# psc3_p8_ppca register map
Vendor: Infineon Technologies; Series: PSC3_P8; File version: 1.0
CPU: CM33 r0p1, little endian, MPU, FPU, DSP, VTOR, 3 interrupt priority bits, 143 interrupts
Registers are 32-bit, read-write, reset 0x0 unless marked. A register's access mark holds for its fields unless they carry their own. Offsets are from the block's base; [hi:lo] are bit positions; lines under a group give offsets from that group; {n}, {i} and the like mark numbered series; 'fields as' and 'values as' point back to an identical list; <NAME> marks a mode.

## SRSS (part 2 of 2) — SRSS Core Registers
Base 0x68200000
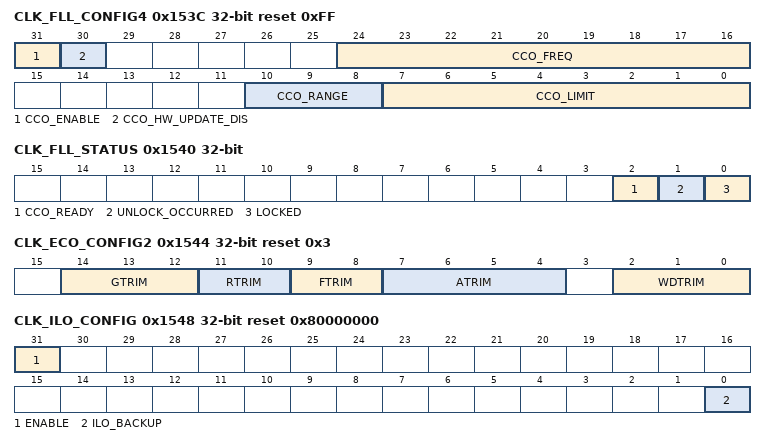
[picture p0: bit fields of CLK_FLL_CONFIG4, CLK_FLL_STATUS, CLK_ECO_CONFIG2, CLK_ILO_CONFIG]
0x153C CLK_FLL_CONFIG4 reset 0xFF — FLL Configuration Register 4
  [31] CCO_ENABLE — Enable the CCO. It is required to enable the CCO before using the FLL. 0: Block is powered off 1: Block is powered on
  [30] CCO_HW_UPDATE_DIS — Disable CCO frequency update by FLL hardware 0: Hardware update of CCO settings is allowed. Use this setting for normal FLL operation. 1: Hardware update of CCO settings is disabled. Use this setting for open-loop FLL operation.
  [24:16] CCO_FREQ — CCO frequency code. This is updated by HW when the FLL is enabled. It can be manually updated to use the CCO in an open loop configuration. The meaning of each frequency code depends on the range.
  [10:8] CCO_RANGE — Frequency range of CCO
    0=RANGE0 (Target frequency is in range [48, 64) MHz); 1=RANGE1 (Target frequency is in range [64, 85) MHz); 2=RANGE2 (Target frequency is in range [85, 113) MHz); 3=RANGE3 (Target frequency is in range [113, 150) MHz); 4=RANGE4 (Target frequency is in range [150, 200] MHz)
  [7:0] CCO_LIMIT — Maximum CCO offset allowed (used to prevent FLL dynamics from selecting an CCO frequency that the logic cannot support)
0x1540 CLK_FLL_STATUS — FLL Status Register
  [2] CCO_READY ro — This indicates that the CCO is internally settled and ready to use.
  [1] UNLOCK_OCCURRED write-1-clears — This bit sets whenever the FLL is enabled and goes out of lock. This bit stays set until cleared by firmware. Note: When exiting Deep Sleep with FLL enabled, UNLOCK_OCCURRED will set. Therefore, after FLL successfully locks, FW should clear UNLOCK_OCCURRED flag to prevent a false positive that would indicate that FLL erroneously unlocked.
  [0] LOCKED ro — FLL Lock Indicator
0x1544 CLK_ECO_CONFIG2 reset 0x3 — ECO Configuration Register 2
  [14:12] GTRIM — Gain Trim - Startup time.
  [11:10] RTRIM — Feedback resistor Trim
  [9:8] FTRIM — Filter Trim - 3rd harmonic oscillation
  [7:4] ATRIM — Amplitude trim to set the crystal drive level when ECO_CONFIG.AGC_EN=1. WARNING: use care when setting this field because driving a crystal beyond its rated limit can permanently damage the crystal. 0x0 - 150mV 0x1 - 175mV 0x2 - 200mV 0x3 - 225mV 0x4 - 250mV 0x5 - 275mV 0x6 - 300mV 0x7 - 325mV 0x8 - 350mV 0x9 - 375mV 0xA - 400mV 0xB - 425mV 0xC - 450mV 0xD - 475mV 0xE - 500mV 0xF - 525mV
  [2:0] WDTRIM — Watch Dog Trim - Delta voltage below steady state level 0x0 - 50mV 0x1 - 75mV 0x2 - 100mV 0x3 - 125mV 0x4 - 150mV 0x5 - 175mV 0x6 - 200mV 0x7 - 225mV
0x1548 CLK_ILO_CONFIG reset 0x80000000 — ILO Configuration
  [31] ENABLE — Master enable for ILO. Writes to this field are ignored unless the WDT is unlocked using WDT_LOCK register. After enabling, it takes at most two cycles to reach the accuracy spec.
  [0] ILO_BACKUP — When BACKUP_PRESENT=0, ILO_BACKUP will not be generated so enabling/disabling ILO will only be controlled by the enable bit. If backup domain is present on this product, this register indicates that ILO should stay enabled for use by backup domain during XRES, HIBERNATE mode, and through power-related resets like BOD on VDDD/VCCD. Writes to this field are ignored unless the WDT is unlocked using WDT_LOCK register. 0: ILO turns off at XRES/BOD event or HIBERNATE entry. 1: ILO remains on if backup domain is present and powered even for XRES/BOD or HIBERNATE entry.
0x154C CLK_TRIM_ILO_CTL reset 0x2C — ILO Trim Register
  [5:0] ILO_FTRIM — IL0 frequency trims. LSB step size is 1.5 percent (typical) of the frequency.
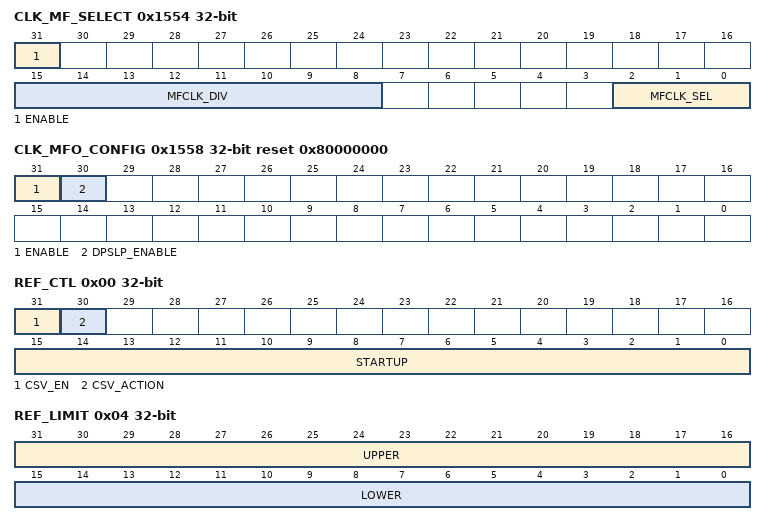
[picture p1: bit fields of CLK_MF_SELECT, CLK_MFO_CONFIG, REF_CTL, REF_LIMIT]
0x1554 CLK_MF_SELECT — Medium Frequency Clock Select Register
  [31] ENABLE — Enable for MFCLK (clk_mf). When disabling clk_mf, do not disable the source until after 5 clk_mf periods. clk_mf continues to operate in DEEPSLEEP for compatible sources. Firmware must disable clk_mf before entering DEEPSLEEP if the source is not compatible with DEEPSLEEP mode.
  [15:8] MFCLK_DIV — Divide selected clock source by (1+MFCLK_DIV). The output of this divider is MFCLK (clk_mf). Allows for integer divisions in the range [1, 256]. Do not change this setting while ENABLE==1.
  [2:0] MFCLK_SEL — Select source for MFCLK (clk_mf). Note that not all products support all clock sources. Selecting a clock source that is not supported results in undefined behavior.
    0=MFO (MFO - Medium Frequency Oscillator. DEEPSLEEP compatibility is product-specific. See CLK_MFO_CONFIG for capability of this product.); 1=ILO (ILO - Internal Low-speed Oscillator.); 2=WCO (WCO - Watch-Crystal Oscillator, if present.); 3=ALTLF (ALTLF - Alternate Low-Frequency Clock. Capability is product-specific); 4=PILO (PILO - Precision ILO, if present.); 5=ILO1 (ILO1 - Internal Low-speed Oscillator #1, if present.); 6=ECO_PRESCALER (ECO_PRESCALER - External-Crystal Oscillator, if present, after prescaling in CLK_ECO_PRESCALE. Intended for applications that operate in ACTIVE/SLEEP modes only. Does not work in DEEPSLEEP mode.); 7=LPECO (LPECO - Low Power External Crystal Oscillator, if present.)
0x1558 CLK_MFO_CONFIG reset 0x80000000 — MFO Configuration Register
  [31] ENABLE — Enable for Medium Frequency Oscillator (MFO) to generate clk_mf. It is product-specific whether this is a separate component or implemented as a divided version of another clock (eg. IMO).
  [30] DPSLP_ENABLE — Enable for MFO during DEEPSLEEP. This bit is ignored when ENABLE==0. When ENABLE==1: 0: MFO is automatically disabled during DEEPSLEEP and enables upon wakeup; 1: MFO is kept enabled throughout DEEPSLEEP
0x1560 CLK_IHO_CONFIG reset 0x80000000 — IHO Configuration Register
  [31] ENABLE — Enable for Internal High-speed Oscillator (IHO) to generate clk_iho.
0x1700 CSV_REF_SEL — Select CSV Reference clock for Active domain
  [2:0] REF_MUX — Selects a source for clock clk_ref_hf. Note that not all products support all clock sources. Selecting a clock source that is not supported will result in undefined behavior. It takes four cycles of the originally selected clock to switch away from it. Do not disable the original clock during this time.
    0=IMO (IMO - Internal R/C Oscillator); 1=EXTCLK (EXTCLK - External Clock Pin); 2=ECO (ECO - External-Crystal Oscillator); 3=ALTHF (ALTHF - Alternate High-Frequency clock input (product-specific clock)); 4=IHO (IHO - Internal High-speed Oscillator)
0x1710 CSV_REF group — CSV registers for the CSV Reference clock
  0x00 CSV group — Active domain Clock Supervisor (CSV) registers for CSV Reference clock
    0x00 REF_CTL — Clock Supervision Reference Control
      [31] CSV_EN — Enables clock supervision, both frequency and loss. CSV in Active domain: Clock supervision is reset during DeepSleep and Hibernate modes. When enabled it begins operating automatically after a DeepSleep wakeup, but it must be reconfigured after Hibernate wakeup. CSV in DeepSleep domain: Clock supervision is reset during Hibernate mode. It must be reconfigured after Hibernate wakeup. A CSV error detection is reported to the Fault structure, or instead it can generate a power reset.
      [30] CSV_ACTION — Specifies the action taken when an anomaly is detected on the monitored clock. CSV in DeepSleep domain always do a Fault report (which also wakes up the system).
        0=FAULT (Generate a fault); 1=RESET (Cause a power reset. This should only be used for clk_hf0.)
      [15:0] STARTUP — Startup delay time -1 (in reference clock cycles), after enable or DeepSleep wakeup, from reference clock start to monitored clock start. At a minimum (both clocks running): STARTUP >= (PERIOD +3) * FREQ_RATIO - UPPER, with FREQ_RATIO = (Reference frequency / Monitored frequency) On top of that the actual clock startup delay and the margin for accuracy of both clocks must be added.
    0x04 REF_LIMIT — Clock Supervision Reference Limits
      [31:16] UPPER — Cycle time upper limit. Set the upper limit -1, in reference clock cycles, before (or same time) the next monitored clock event must happen. If a monitored clock event does not happen before this limit is reached, or does not happen at all (clock loss), a CSV error is detected.
      [15:0] LOWER — Cycle time lower limit. Set the lower limit -1, in reference clock cycles, before the next monitored clock event is allowed to happen. If a monitored clock event happens before this limit is reached a CSV error is detected. LOWER must be at least 1 less than UPPER. In case the clocks are asynchronous LOWER must be at least 3 less than UPPER.
    0x08 MON_CTL — Clock Supervision Monitor Control
      [15:0] PERIOD — Period time. Set the Period -1, in monitored clock cycles, before the next monitored clock event happens. PERIOD <= (UPPER+1) / FREQ_RATIO -1, with FREQ_RATIO = (Reference frequency / Monitored frequency) In case the clocks are asynchronous: PERIOD <= UPPER / FREQ_RATIO -1 Additionally margin must be added for accuracy of both clocks.
0x1720 CSV_LF group — CSV registers for LF clock
  0x00 CSV group — LF clock Clock Supervisor registers
    0x00 REF_CTL — Clock Supervision Reference Control
      [31] CSV_EN — Enables clock supervision, both frequency and loss. CSV in Active domain: Clock supervision is reset during DeepSleep and Hibernate modes. When enabled it begins operating automatically after a DeepSleep wakeup, but it must be reconfigured after Hibernate wakeup. CSV in DeepSleep domain: Clock supervision is reset during Hibernate mode. It must be reconfigured after Hibernate wakeup. CSV in Backup domain: Clock supervision operates during Hibernate mode, can be configured to wake from Hibernate, and continues operating during reboot. A CSV error detection is reported to the Fault structure.
      [7:0] STARTUP — Startup delay time -1 (in reference clock cycles), after enable, from reference clock start to monitored clock start. At a minimum (both clocks running): STARTUP >= (PERIOD +3) * FREQ_RATIO - UPPER, with FREQ_RATIO = (Reference frequency / Monitored frequency) On top of that the actual clock startup delay and the margin for accuracy of both clocks must be added.
    0x04 REF_LIMIT — Clock Supervision Reference Limits
      [23:16] UPPER — Cycle time upper limit. Set the upper limit -1, in reference clock cycles, before (or same time) the next monitored clock event must happen. If a monitored clock event does not happen before this limit is reached, or does not happen at all (clock loss), a CSV error is detected.
      [7:0] LOWER — Cycle time lower limit. Set the lower limit -1, in reference clock cycles, before the next monitored clock event is allowed to happen. If a monitored clock event happens before this limit is reached a CSV error is detected. LOWER must be at least 1 less than UPPER. In case the clocks are asynchronous LOWER must be at least 3 less than UPPER.
    0x08 MON_CTL — Clock Supervision Monitor Control
      [7:0] PERIOD — Period time. Set the Period -1, in monitored clock cycles, before the next monitored clock event happens. PERIOD <= (UPPER+1) / FREQ_RATIO -1, with FREQ_RATIO = (Reference frequency / Monitored frequency) In case the clocks are asynchronous: PERIOD <= UPPER / FREQ_RATIO -1 Additionally margin must be added for accuracy of both clocks.
0x1730 CSV_ILO group — CSV registers for ILO clock
  0x00 CSV group — HVILO clock DeepSleep domain Clock Supervisor registers
    0x00 REF_CTL — Clock Supervision Reference Control
      fields as CSV_LF.CSV.REF_CTL
    0x04 REF_LIMIT — Clock Supervision Reference Limits
      fields as CSV_LF.CSV.REF_LIMIT
    0x08 MON_CTL — Clock Supervision Monitor Control
      fields as CSV_LF.CSV.MON_CTL
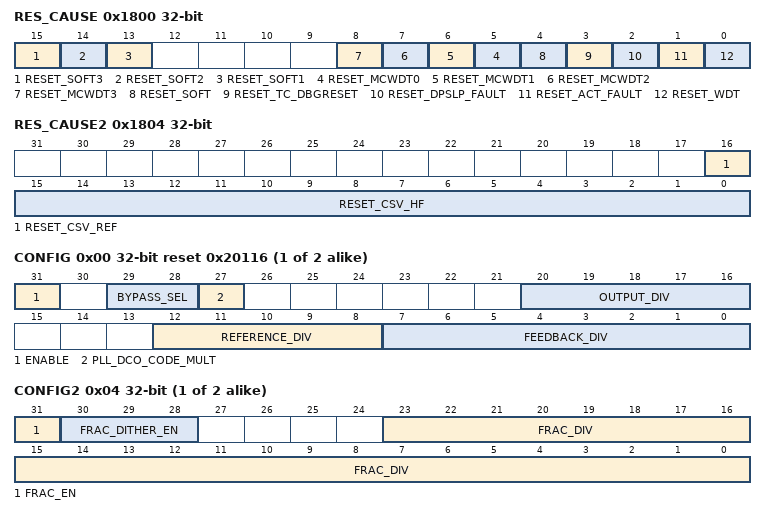
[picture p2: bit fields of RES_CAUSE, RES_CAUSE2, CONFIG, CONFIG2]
0x1800 RES_CAUSE — Reset Cause Observation Register
  [15] RESET_SOFT3 write-1-clears — CPU[3] requested a system reset through it's SYSRESETREQ. This can be done via a debugger probe or in firmware. This is a low-voltage cause bit that hardware clears when the low-voltage supply is initialized (see comments above).
  [14] RESET_SOFT2 write-1-clears — CPU[2] requested a system reset through it's SYSRESETREQ. This can be done via a debugger probe or in firmware. This is a low-voltage cause bit that hardware clears when the low-voltage supply is initialized (see comments above).
  [13] RESET_SOFT1 write-1-clears — CPU[1] requested a system reset through it's SYSRESETREQ. This can be done via a debugger probe or in firmware. This is a low-voltage cause bit that hardware clears when the low-voltage supply is initialized (see comments above).
  [n+5] RESET_MCWDT{n} write-1-clears (n=0..3) — Multi-Counter Watchdog timer reset #{n}. This is a low-voltage cause bit that hardware clears when the low-voltage supply is initialized (see comments above). This bit is only valid when parameter NUM_MCWDT>{n}
  [4] RESET_SOFT write-1-clears — CPU[0] requested a system reset through it's SYSRESETREQ. This can be done via a debugger probe or in firmware. This is a low-voltage cause bit that hardware clears when the low-voltage supply is initialized (see comments above).
  [3] RESET_TC_DBGRESET write-1-clears — Test controller or debugger asserted reset. Only resets debug domain. This is a low-voltage cause bit that hardware clears when the low-voltage supply is initialized (see comments above).
  [2] RESET_DPSLP_FAULT write-1-clears
  [1] RESET_ACT_FAULT write-1-clears
  [0] RESET_WDT write-1-clears — A basic WatchDog Timer (WDT) reset has occurred since last power cycle. ULP products: This is a low-voltage cause bit that hardware clears when the low-voltage supply is initialized (see comments above). For products that support high-voltage cause detection, this bit blocks recording of other high-voltage cause bits, except RESET_PORVDDD. Hardware clears this bit during POR. This bit is not blocked by other HV cause bits.
0x1804 RES_CAUSE2 — Reset Cause Observation Register 2
  [16] RESET_CSV_REF write-1-clears — Clock supervision logic requested a reset due to loss or frequency violation of the reference clock source that is used to monitor the other HF clock sources. This bit is only valid when parameter CSV_PRESENT is set.
  [15:0] RESET_CSV_HF write-1-clears — Clock supervision logic requested a reset due to loss or frequency violation of a high-frequency clock. Each bit index K corresponds to a HFCLK<K>. Unimplemented clock bits return zero. Each bit is only valid when the corresponding bit in parameter MASK_HFCSV is 1 and CSV_PRESENT is set.
0x1814 RES_PXRES_CTL wo — Programmable XRES Control Register
  [0] PXRES_TRIGGER write-1-sets — Triggers PXRES. This causes a full-scope reset and reboot.
{0x1A00+0x20*i} CLK_DPLL_LP[{i}] (i=0..1) group — DPLL LP Configuration Register
  0x00 CONFIG reset 0x20116 — DPLL_LP Configuration Register
    [31] ENABLE — Master enable for PLL. Setup FEEDBACK_DIV, REFERENCE_DIV, and OUTPUT_DIV at least one cycle before setting ENABLE=1. fOUT = (FEEDBACK_DIV + FRAC_EN*FRAC_DIV/2^24) * (fREF / REFERENCE_DIV) / (OUTPUT_DIV) 0: Block is disabled. When the PLL disables, hardware controls the bypass mux as described in BYPASS_SEL, before disabling the PLL circuit. 1: Block is enabled
    [29:28] BYPASS_SEL — Bypass mux located just after PLL output. This selection is glitch-free and can be changed while the PLL is running. When changing BYPASS_SEL, do not turn off the reference clock or PLL clock for five cycles (whichever is slower).
      0=AUTO (Automatic using lock indicator. When unlocked, automatically selects PLL reference input (bypass mode). When locked, automatically selects PLL output. If ENABLE=0, automatically selects PLL reference input.); 1=LOCKED_OR_NOTHING (Similar to AUTO, except the clock is gated off when unlocked. This is compatible with clock supervision, because the supervisors allow no clock during startup (until a timeout occurs), and the clock targets the proper frequency whenever it is running. If ENABLE=0, no clock is output.); 2=PLL_BYPASS (Select PLL reference input (bypass mode). Ignores lock indicator); 3=PLL_OUT (Select PLL output. Ignores lock indicator. If ENABLE=0, no clock is output.)
    [27] PLL_DCO_CODE_MULT — DCO code coefficient during SAR operation; this trim bit is Fpfd frequency dependent 0: multilply by 16, Fpfd <= 8MHZ 1: mulitply by 28, Fpfd > 8MHz
    [20:16] OUTPUT_DIV — Control bits for Output divider. Set the divide value before enabling the PLL, and do not change it while PLL is enabled. 0: illegal (undefined behavior) 1: divide by 1. Suitable for direct usage as HFCLK source. 2: divide by 2. Suitable for direct usage as HFCLK source. ... 16: divide by 16. Suitable for direct usage as HFCLK source. >16: illegal (undefined behavior)
    [12:8] REFERENCE_DIV — Control bits for reference divider. Set the divide value before enabling the PLL, and do not change it while PLL is enabled. 0: illegal (undefined behavior) 1: divide by 1 ... 16: divide by 16 others: illegal (undefined behavior)
    [7:0] FEEDBACK_DIV — Control bits for feedback divider. Set the divide value before enabling the PLL, and do not change it while PLL is enabled. 0-15: illegal (undefined behavior) 16: divide by 16 ... 125: divide by 125 >125: illegal (undefined behavior)
  0x04 CONFIG2 — DPLL_LP Configuration Register 2
    [31] FRAC_EN — Enables fractional division mode.
    [30:28] FRAC_DITHER_EN
    [23:0] FRAC_DIV — Control bits for fractional divider. This value is interpreted as a fraction of the PFD frequency, i.e. fPFD * (FRAC_DIV/2^24). This field can be dynamically updated within the 1000ppm control limit. It takes up to 115 AHB cycles to transfer the setting to the PLL, and writes that occur faster may be silently ignored and require the application to write again after the previous update has finished. Reading the register returns the accepted value. The PLL will start targeting the new value, but it may take significant time (milliseconds) to stabilize at the new average value. Do not change the FRAC_DIV setting while the PLL is initially locking.
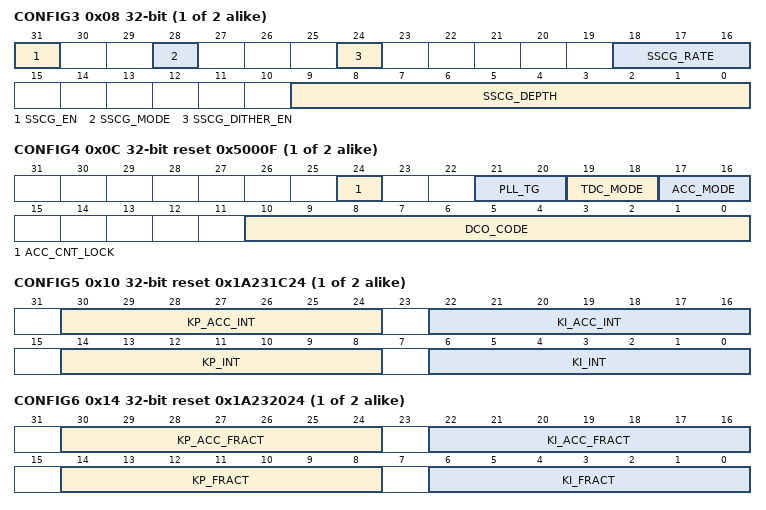
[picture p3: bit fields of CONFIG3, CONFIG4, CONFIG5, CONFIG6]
  0x08 CONFIG3 — DPLL_LP Configuration Register 3
    [31] SSCG_EN — Enables spreading mode. When SSCG mode is enabled, DPLL_LP_TEST4.PLL_DIS_FAST_LOCK should be set to 1 to disable fast re-lock.
    [28] SSCG_MODE
    [24] SSCG_DITHER_EN
    [18:16] SSCG_RATE
    [9:0] SSCG_DEPTH
  0x0C CONFIG4 reset 0x5000F — DPLL_LP Configuration Register 4
    [24] ACC_CNT_LOCK — Control signal for switching to stable filter coefficients (PLL_KP_TRIM/PLL_KI_TRIM) 0: PLL_ACC_PHASE_CNT_DONE 1: PLL_LOCK
    [21:20] PLL_TG — This value is a number of PFD clocks in relation to the DCO count. Can change the number of counts, set by p_div in integer mode, by the values of -1, +1, or +2. 0: 0 1: -1 2: +1 3: +2 In integer and SSCG mode, PLL_TG must be set to 0. If in fractional mode, PLL_TG must be 0 if frac_ratio <= 0.5 (pll_frac <= 2^23), PLL_TG must be 2 if frac_ratio > 0.5 (pll_frac > 2^23).
    [19:18] TDC_MODE
    [17:16] ACC_MODE
    [10:0] DCO_CODE — Initial DCO code. It is recommended to leave this at the default setting. This setting only has effect in open loop mode. See DPLL BROS regarding test modes.
  0x10 CONFIG5 reset 0x1A231C24 — DPLL_LP Configuration Register 5
    [30:24] KP_ACC_INT — Gain of P/I loop filter integrator path during cold start for INT operation. Gain coefficient is 2^KP, eg. 0=>1, 15=>32768.
    [22:16] KI_ACC_INT — Gain of P/I loop filter integrator path during cold start for INT operation. Gain coefficient is 2^KI, eg. 0=>1, 15=>32768.
    [14:8] KP_INT — Gain of P/I loop filter integrator path for INT operation. Gain coefficient is 2^KP, eg. 0=>1, 15=>32768.
    [6:0] KI_INT — Gain of P/I loop filter integrator path for INT operation. Gain coefficient is 2^KI, eg. 0=>1, 15=>32768.
  0x14 CONFIG6 reset 0x1A232024 — DPLL_LP Configuration Register 6
    [30:24] KP_ACC_FRACT — Gain of P/I loop filter integrator path during cold start for FRACT operation. Gain coefficient is 2^KP, eg. 0=>1, 15=>32768.
    [22:16] KI_ACC_FRACT — Gain of P/I loop filter integrator path during cold start for FRACT operation. Gain coefficient is 2^KI, eg. 0=>1, 15=>32768.
    [14:8] KP_FRACT — Gain of P/I loop filter proportional path for FRACT operation. Gain coefficient is 2^KP, eg. 0=>1, 15=>32768.
    [6:0] KI_FRACT — Gain of P/I loop filter proportional path for FRACT operation. Gain coefficient is 2^KI, eg. 0=>1, 15=>32768.
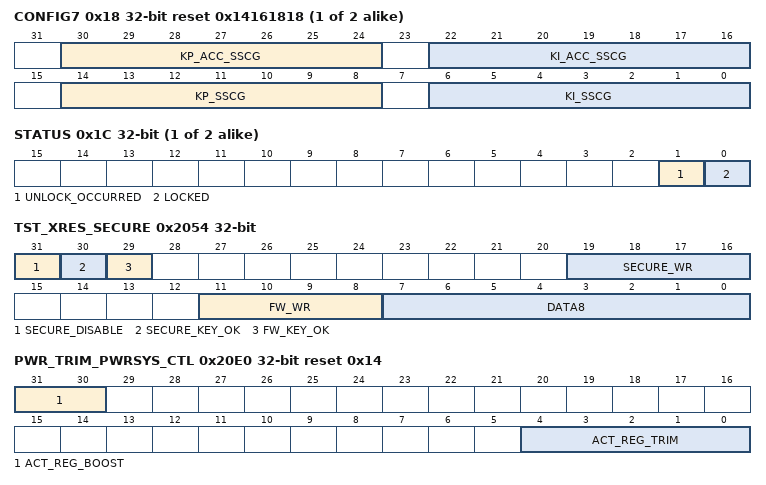
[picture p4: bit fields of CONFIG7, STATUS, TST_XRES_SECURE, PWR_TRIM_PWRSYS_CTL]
  0x18 CONFIG7 reset 0x14161818 — DPLL_LP Configuration Register 7
    [30:24] KP_ACC_SSCG — Gain of P/I loop filter integrator path during cold start for SSCG operation. Gain coefficient is 2^KP, eg. 0=>1, 15=>32768.
    [22:16] KI_ACC_SSCG — Gain of P/I loop filter integrator path during cold start for SSCG operation. Gain coefficient is 2^KI, eg. 0=>1, 15=>32768.
    [14:8] KP_SSCG — Gain of P/I loop filter proportional path for SSCG operation. Gain coefficient is 2^KP, eg. 0=>1, 15=>32768.
    [6:0] KI_SSCG — Gain of P/I loop filter proportional path for SSCG operation. Gain coefficient is 2^KI, eg. 0=>1, 15=>32768.
  0x1C STATUS — DPLL_LP Status Register
    [1] UNLOCK_OCCURRED write-1-clears — This bit sets whenever the PLL Lock bit goes low, and stays set until cleared by firmware. Note: When disabling DPLL via register write, UNLOCK_OCCURRED will set. Therefore, after enabling DPLL and DPLL successfully locks, FW should clear UNLOCK_OCCURRED flag to prevent a false positive that would indicate that DPLL erroneously unlocked.
    [0] LOCKED ro — PLL Lock Indicator
0x2054 TST_XRES_SECURE — SECURE TEST and FIRMWARE TEST Key control register
  [31] SECURE_DISABLE write-1-sets — Disables the SECURE TEST key entry capability until next reset. Must not be set in the same write when any of the above *_WR bits are set or toggling.
  [30] SECURE_KEY_OK ro — Indicates that the 32-bit SECURE TEST key is observing the correct key. Secure key is not reset, but it will establish low after a deep power cycle that causes it to lose its written state.
  [29] FW_KEY_OK ro — Indicates that the 32-bit FIRMWARE TEST key is observing the correct key. Firmware key is reset by (A)XRES and STRUCT_XRES.
  [19:16] SECURE_WR — Latch enables for each of the 4 bytes in the 32-bit SECURE TEST key. Must be toggled high and then low while keeping DATA8 to the correct value.
  [11:8] FW_WR — Latch enables for each of the 4 bytes in the 32-bit FIRMWARE TEST key. Must be toggled high and then low while keeping DATA8 to the correct value.
  [7:0] DATA8 — Data byte to be set into either SECURE TEST or FIRMWARE TEST key. Must not be changed in the same write that is toggling any of the *_WR bits below,
0x20E0 PWR_TRIM_PWRSYS_CTL reset 0x14 (reset mask 0x1F) — Power System Trim Register
  [31:30] ACT_REG_BOOST — Controls the tradeoff between output current and internal operating current for the Active Regulator. The maximum output current depends on the silicon implementation, but an application may limit its maximum current to less than that. This may allow a reduction in the internal operating current of the regulator. The regulator internal operating current depends on the boost setting: 2'b00: 50uA 2'b01: 100uA 2'b10: 150uA 2'b11: 200uA The allowed setting is a lookup table based on the chip-specific maximum (set in factory) and an application-specific maximum (set by customer). The defaults are set assuming the application consumes the maximum allowed by the chip. 50mA chip: 2'b00 (default); 100mA chip: 2'b00 (default); 150mA chip: 50..100mA app => 2'b00, 150mA app => 2'b01 (default); 200mA chip: 50mA app => 2'b00, 100..150mA app => 2'b01, 200mA app => 2'b10 (default); 250mA chip: 50mA app => 2'b00, 100..150mA app => 2'b01, 200..250mA app => 2'b10 (default); 300mA chip: 50mA app => 2'b00, 100..150mA app => 2'b01, 200..250mA app => 2'b10, 300mA app => 2'b11 (default); This register is only reset by XRES, HIBERNATE wakeup, or supply supervision reset.
  [4:0] ACT_REG_TRIM — Trim for the Active-Regulator. This sets the output voltage level. This register is only reset by XRES, HIBERNATE wakeup, or supply supervision reset. The nominal output voltage is vccd=850mV + ACT_REG_TRIM*12.5mV. The actual output voltage will vary depending on conditions and load. The following settings are explicitly shown for convenience, and other values may be calculated using the formula: 5'h04: 900mV (nominal) 5'h0C: 1000mV (nominal) 5'h14: 1100mV (nominal) 5'h1C: 1200mV (nominal)
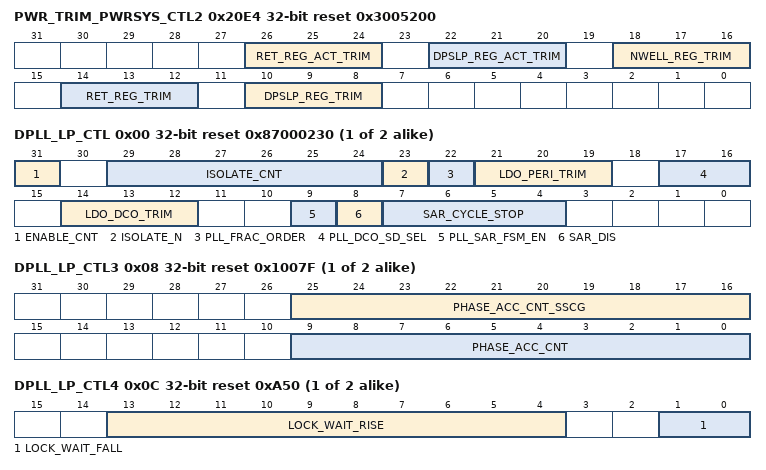
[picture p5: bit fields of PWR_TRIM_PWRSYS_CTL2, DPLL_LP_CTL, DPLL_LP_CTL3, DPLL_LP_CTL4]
0x20E4 PWR_TRIM_PWRSYS_CTL2 reset 0x3005200 — Power System Trim Register 2
  [26:24] RET_REG_ACT_TRIM — Trim for the Retention-Regulator (if present) applied during (LP)ACTIVE/(LP)SLEEP modes. These are expected to be constant but provided as registers for risk mitigation. This register is only reset by XRES, HIBERNATE wakeup, or supply supervision reset.
  [22:20] DPSLP_REG_ACT_TRIM — Trim for the DeepSleep-Regulator applied during (LP)ACTIVE/(LP)SLEEP modes. These are expected to be constant but provided as registers for risk mitigation. This register is only reset by XRES, HIBERNATE wakeup, or supply supervision reset.
  [18:16] NWELL_REG_TRIM — Trim for the Nwell-Regulator (if present) applied during DEEPSLEEP mode. Nwell trim is always forced to zero during (LP)ACTIVE/(LP)SLEEP modes. This register is only reset by XRES, HIBERNATE wakeup, or supply supervision reset.
  [14:12] RET_REG_TRIM — Trim for the Retention-Regulator (if present) applied during DEEPSLEEP mode. This register is only reset by XRES, HIBERNATE wakeup, or supply supervision reset.
  [10:8] DPSLP_REG_TRIM — Trim for the DeepSleep-Regulator applied during DEEPSLEEP mode. This register is only reset by XRES, HIBERNATE wakeup, or supply supervision reset. 0: 0.825V 1: 0.850V 2: 0.875V 3: 0.900V 4: 0.925V 5: 1.050V 6: 1.100V 7: 1.150V
0x301C CLK_TRIM_ECO_CTL reset 0x1F0000 — ECO Trim Register
  [21:16] ITRIM — Current Trim
0x4000 RAM_TRIM group — SRAM Trim registers
  0x00 TRIM_RAM_CTL — Trim Register for RAM Type 0
    [31:0] TRIM
  0x04 TRIM_ROM_CTL — Trim Register for ROM
    [31:0] TRIM
{0x4200+0x20*i} CLK_TRIM_DPLL_LP[{i}] (i=0..1) group — DPLL LP Trims
  0x00 DPLL_LP_CTL reset 0x87000230 — DPLL LP Trim Register
    [31] ENABLE_CNT — Enable for the PLL hardware sequencer. 0: Disables the hardware sequencer. Before enabling the DPLL manually make sure to have DPLL_LP_STRUCT_Regs->CONFIG->BYPASS_SEL at default value to avoid unwanted glitch on clock HF root. When disabling the PLL, first deselect it using .BYPASS_SEL=PLL_REF, wait at least six PLL clock cycles, and then disable it with .ENABLE=0. Before entering DEEPSLEEP, firmware must switch to another clock source and disable the PLL. 1: Enables the hardware sequencer. The sequencer handles all PLL enable/disable transitions, including around DEEPSLEEP entry/exit.
    [29:24] ISOLATE_CNT — Terminal count for the stabilization counter handles PLL_ISOLATE_N
    [23] ISOLATE_N — Manual isolation control for PLL . This field is ignored when ENABLE_CNT==1. When controlling manually, de-assert >= 3us after ENABLE=1. Assertion can happen in cycle just before ENABLE=0. 0: Isolate outputs 1: Do not isolate outputs
    [22] PLL_FRAC_ORDER — Order of the delta-sigma modulator used for fractional mode. If DPLL_LP_STRUCT_Regs.CONFIG4.ACC_MODE = 00b: 0: 4th order 1: 3rd order If DPLL_LP_STRUCT_Regs.CONFIG4.ACC_MODE = 01b: 0: 2nd order 1: 1st order
    [21:19] LDO_PERI_TRIM — pll ldo peripheri voltage trim (scan mode - can be '0' or '1' - not High Z)
    [17:16] PLL_DCO_SD_SEL — 00': disable, '01' first order SigmaDelta enabled;'10' third order SigmaDelta enabled;'11' RSVD
    [14:12] LDO_DCO_TRIM — Trim for PLL local regulator for DCO 0 0.906V 1 0.786V 2 0.846V 3 0.876V 4 0.936V 5 0.966V
    [9] PLL_SAR_FSM_EN — SAR FSM enable. Always set to 1 for functional mode. This register was kept in the design (and moved to hidden trim register) to increase coverage on the hard IP, and could be removed once the hard IP input is removed.
    [8] SAR_DIS — Disable Successive Approximation Register during locking. 0: Use SAR. 1: Disable SAR.
    [7:4] SAR_CYCLE_STOP — Successive Approximation Register (SAR) configuration. Ignored when SAR_DIS==1. 0x1...0xB: Number of cycles until SAR stops. others: illegal Note: For initial lock, default should be left at 0x3. After successful lock with code write = 0, FW should set to 0x1 to improve recovery time for successive locks.
  0x08 DPLL_LP_CTL3 reset 0x1007F — DPLL LP Trim Register 3
    [25:16] PHASE_ACC_CNT_SSCG — counter for phase accelerate cycles during PLL wakeup SSCG mode Optimal settings: 4 --> 5 MHz: 127 5-->6 MHz: 157 6-->7 MHz: 187 7-->8 MHz: 217 8-->9 MHz: 255 9-->10 MHz: 286 10-->11 MHz: 317 11-->12 MHz: 348 12-->13 MHz: 379 13-->14 MHz: 410 14-->15 MHz: 441 15-->16 MHz: 472 16 MHz: 511
    [9:0] PHASE_ACC_CNT — counter for phase accelerate cycles during PLL wakeup for INT and FRAC modes Optimal settings: 4 --> 5 MHz: 127 5-->6 MHz: 157 6-->7 MHz: 187 7-->8 MHz: 217 8-->9 MHz: 255 9-->10 MHz: 286 10-->11 MHz: 317 11-->12 MHz: 348 12-->13 MHz: 379 13-->14 MHz: 410 14-->15 MHz: 441 15-->16 MHz: 472 16 MHz: 511
  0x0C DPLL_LP_CTL4 reset 0xA50 — DPLL LP Trim Register 4
    [13:4] LOCK_WAIT_RISE — Wait time from when static phase error is within the lock window until lock signal asserts. 0: Illegal 1: 1 PFD clocks 2: 2 PFD clocks ... 1023: 1023 PFD clocks Optimal settings f, MHz With Code Write Without Code Write --------- ------------------------------------ ------------------------------------ 4-->5 6 33 5-->6 6 40 6-->7 6 49 7-->8 8 60 8-->9 8 85 9-->10 11 95 10-->11 12 105 11-->12 14 115 12-->13 15 125 13-->14 17 135 14-->15 18 145 15-->16 20 155 16 21 165 Notes: 1. For initial DPLL locking or when DPLL Fast Lock is disabled (PLL_DIS_FAST_LOCK=1), user must program DPLL_CTL4.LOCK_WAIT_RISE using appropriate value for 'Without Code Write' for corresponding frequency range. 2. After initial DPLL locking, when DPLL Fast Lock is enabled (PLL_DIS_FAST_LOCK=0), before DEEPSLEEP entry, FW must poll the DPLL_LP.STATUS.LOCKED bit to acknowledge successful DPLL lock, then must program DPLL_LP_CTL4.LOCK_WAIT_RISE using appropriate value for 'With Code Write' for corresponding frequency range.
    [1:0] LOCK_WAIT_FALL — Wait time from when static phase error is within the lock window until lock signal asserts. 0: 0 PFD clocks 1: 2 PFD clocks 2: 3 PFD clocks 3: 4 PFD clocks
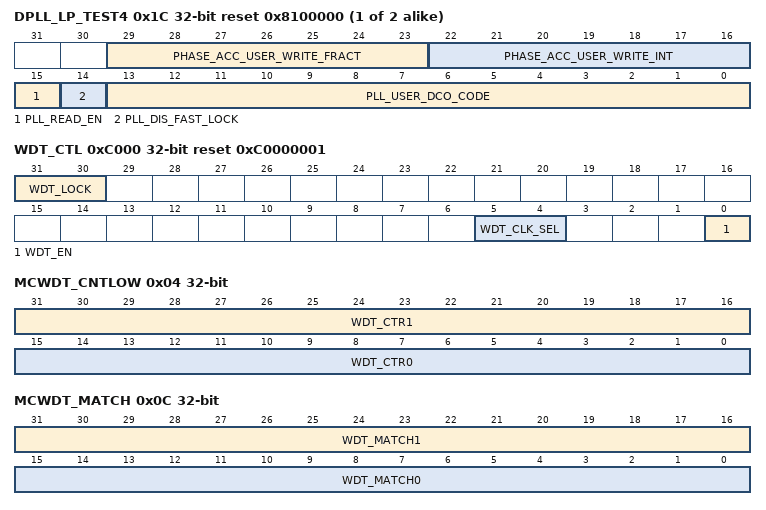
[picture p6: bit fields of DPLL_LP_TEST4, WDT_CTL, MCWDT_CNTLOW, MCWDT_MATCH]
  0x1C DPLL_LP_TEST4 reset 0x8100000 — DPLL LP Test Register 4
    [29:23] PHASE_ACC_USER_WRITE_FRACT — reduce KI,KP coefficient during PLL deepsleep wakeup fract.
    [22:16] PHASE_ACC_USER_WRITE_INT — Reduce KI,KP coefficient during PLL deepsleep wakeup integer.
    [15] PLL_READ_EN — This bit is a self clear bit. The FW writes 1 to get an updated value in PLL_USER_DCO_CODE.HW will self clear this bit to indicate that the PLL_USER_DCO_CODE be read.
    [14] PLL_DIS_FAST_LOCK — 0: Enables DPLL Fast Lock 1: Disables DPLL Fast Lock When PLL_DIS_FAST_LOCK=0, if DPLL successfully locks prior to a DEEPSLEEP entry: - HW will read the DCO code before DEEPSLEEP entry, then write the DCO code upon DEEPSLEEP exit, to reduce DPLL lock time. - FW must follow the procedure described under DPLL_LP_CTL4.LOCK_WAIT_RISE Notes: 2
    [13:0] PLL_USER_DCO_CODE — FW can read the code saved by the DPLL before deepsleep.Use PLL_READ_EN to get updated DCO_CODE from the DPLL: To read properly please refer to PLL_USER_DCO_CODE_RD_EN/PLL_READ_EN. Before any read, FW should check first that PLL_READ_EN is 0. To account for Clock Domain Crossings, FW should wait at least 3 CLK_IMO cycles (3*125ns=375ns) between SW write and SW read operation.
0xC000 WDT_CTL reset 0xC0000001 — Watchdog Counter Control Register (Type A)
  [31:30] WDT_LOCK — Prohibits writing to WDT_*, CLK_ILO_CONFIG, CLK_SELECT.LFCLK_SEL, and CLK_TRIM_ILO_CTL registers when not equal 0. Requires at least two different writes to unlock. A change in WDT_LOCK takes effect beginning with the next write cycle. Note that this field is 2 bits to force multiple writes only. It represents only a single write protect signal protecting all those registers at the same time. WDT will lock on any reset. This field is not retained during DEEPSLEEP or HIBERNATE mode, so the WDT will be locked after wakeup from these modes.
    0=NO_CHG (No effect); 1=CLR0 (Clears bit 0); 2=CLR1 (Clears bit 1); 3=SET01 (Sets both bits 0 and 1)
  [5:4] WDT_CLK_SEL — Select source for WDT. Not all products support all clock sources. Selecting a clock source that is not supported will result in undefined behavior. Writes to this field are ignored unless the WDT is unlock using WDT_LOCK register. It takes four cycles of the originally selected clock to switch away from it. Do not disable the original clock during this time.
    0=ILO (ILO - Internal Low-speed Oscillator); 1=PILO (PILO - Precision ILO. If present, if present); 2=BAK (BAK - Selected clk_bak source, if present. See BACKUP_CTL. This choice is not recommended for applications that rely upon the watchdog timer for safety or security, unless the product supports clock supervision of clk_bak (CSV_BAK). Generation of clk_bak is not protected by WDT_LOCK and is in a different memory region with potentially different security attributes.)
  [0] WDT_EN — Enable this watchdog timer. This field is retained during DEEPSLEEP and HIBERNATE modes.
0xC004 WDT_CNT — Watchdog Counter Count Register (Type A)
  [31:0] COUNTER — Current value of WDT Counter. The write feature of this register is for engineering use (DfV), have no synchronization, and can only be applied when the WDT is fully off. When writing, the value is updated immediately in the WDT counter, but it will read back as the old value until this register resynchronizes just after the negedge of ILO. Writes will be ignored if they occur when the WDT is enabled.
0xC008 WDT_MATCH reset 0x1000 — Watchdog Counter Match Register (Type A)
  [31:0] MATCH — Match value for Watchdog counter. Every time WDT_COUNTER reaches MATCH an interrupt is generated. Two unserviced interrupts will lead to a system reset (i.e. at the third match).
0xC00C WDT_MATCH2 reset 0x1F — Watchdog Counter Match Register 2 (Type A)
  [4:0] IGNORE_BITS_ABOVE — The bit index to be considered the MSB for matching. Bit indices above this setting are NOT checked against MATCH. This value provides control over the time-to-reset of the watchdog (which happens after 3 successive matches). The four LSBs cannot be ignored for matching. Settings <3 behave like a setting of 3. If the setting is higher than the number of bits in the WDT counter, all actual bits in the counter are matched.
0xD000 MCWDT_STRUCT group — Multi-Counter Watchdog Timer (Type A)
  0x04 MCWDT_CNTLOW — Multi-Counter Watchdog Sub-counters 0/1
    [31:16] WDT_CTR1 — Current value of sub-counter 1 for this MCWDT. Software writes are ignored when the sub-counter is enabled
    [15:0] WDT_CTR0 — Current value of sub-counter 0 for this MCWDT. Software writes are ignored when the sub-counter is enabled.
  0x08 MCWDT_CNTHIGH — Multi-Counter Watchdog Sub-counter 2
    [31:0] WDT_CTR2 — Current value of sub-counter 2 for this MCWDT. Software writes are ignored when the sub-counter is enabled
  0x0C MCWDT_MATCH — Multi-Counter Watchdog Counter Match Register
    [31:16] WDT_MATCH1 — Match value for sub-counter 1 of this MCWDT
    [15:0] WDT_MATCH0 — Match value for sub-counter 0 of this MCWDT
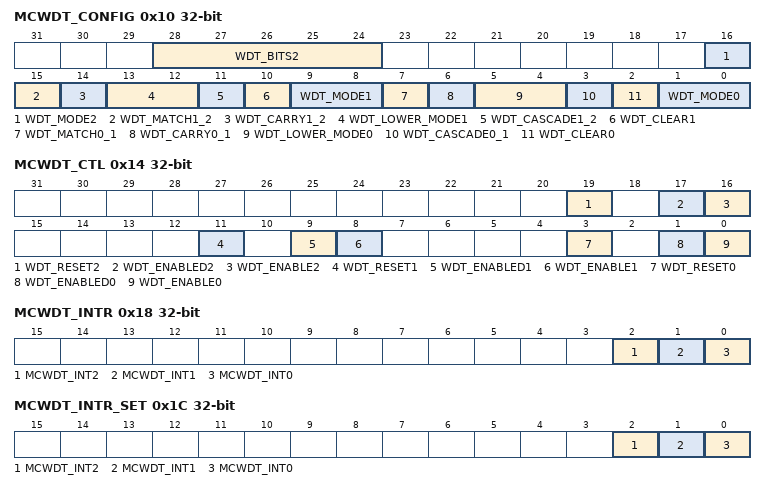
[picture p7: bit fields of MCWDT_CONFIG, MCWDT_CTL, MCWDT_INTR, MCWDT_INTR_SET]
  0x10 MCWDT_CONFIG — Multi-Counter Watchdog Counter Configuration
    [28:24] WDT_BITS2 — Bit to observe for WDT_INT2: 0: Assert after bit0 of WDT_CTR2 toggles (one int every tick) ... 31: Assert after bit31 of WDT_CTR2 toggles (one int every 2^31 ticks)
    [16] WDT_MODE2 — Watchdog Counter 2 Mode.
      0=NOTHING (Free running counter with no interrupt requests); 1=INT (Free running counter with interrupt request that occurs one LFCLK cycle after the specified bit in CTR2 toggles (see WDT_BITS2).)
    [15] WDT_MATCH1_2 — Specifies matching behavior when WDT_CASCADE1_2==1. When WDT_CASCADE1_2==0, this bit is not used and match is based on counter 2 alone. 0: Match based on counter 2 alone. 1: Match based on counter 2 and counter 1 matching simultaneously.
    [14] WDT_CARRY1_2 — Carry out behavior that applies when WDT_CASCADE1_2==1. This bit is not used when WDT_CASCADE1_2==0. 0: carry out on counter 1 match. 1: carry out on counter 1 roll-over.
    [13:12] WDT_LOWER_MODE1 — Watchdog Counter Action on service before lower limit.
      0=NOTHING (Do nothing); 1=INT (Assert WDT_INTx); 2=RESET (Assert WDT Reset)
    [11] WDT_CASCADE1_2 — Cascade Watchdog Counters 1,2. Counter 2 increments the cycle after WDT_CTR1=WDT_MATCH1. It is allowed to cascade all three WDT counters. 0: Independent counters 1: Cascaded counters. When cascading all three counters, WDT_CLEAR1 must be 1.
    [10] WDT_CLEAR1 — Clear Watchdog Counter when WDT_CTR1==WDT_MATCH1. In other words WDT_CTR1 divides LFCLK by (WDT_MATCH1+1). 0: Free running counter 1: Clear on match. In this mode, the minimum legal setting of WDT_MATCH1 is 1.
    [9:8] WDT_MODE1 — Watchdog Counter Action on Match. Action is taken on the next increment after the values match (WDT_CTR1=WDT_MATCH1).
      0=NOTHING (Do nothing); 1=INT (Assert WDT_INTx); 2=RESET (Assert WDT Reset); 3=INT_THEN_RESET (Assert WDT_INTx, assert WDT Reset after 3rd unhandled interrupt)
    [7] WDT_MATCH0_1 — Specifies matching behavior when WDT_CASCADE0_1==1. When WDT_CASCADE0_1==0, this bit is not used and match is based on counter 1 alone. 0: Match based on counter 1 alone. 1: Match based on counter 1 and counter 0 matching simultaneously.
    [6] WDT_CARRY0_1 — Carry out behavior that applies when WDT_CASCADE0_1==1. This bit is not used when WDT_CASCADE0_1==0. 0: carry out on counter 0 match. 1: carry out on counter 0 roll-over.
    [5:4] WDT_LOWER_MODE0 — Watchdog Counter Action on service before lower limit.
      values as WDT_LOWER_MODE1
    [3] WDT_CASCADE0_1 — Cascade Watchdog Counters 0,1. Counter 1 increments the cycle after WDT_CTR0=WDT_MATCH0. 0: Independent counters 1: Cascaded counters
    [2] WDT_CLEAR0 — Clear Watchdog Counter when WDT_CTR0=WDT_MATCH0. In other words WDT_CTR0 divides LFCLK by (WDT_MATCH0+1). 0: Free running counter 1: Clear on match. In this mode, the minimum legal setting of WDT_MATCH0 is 1.
    [1:0] WDT_MODE0 — Watchdog Counter Action on Match. Action is taken on the next increment after the values match (WDT_CTR0=WDT_MATCH0).
      values as WDT_MODE1
  0x14 MCWDT_CTL — Multi-Counter Watchdog Counter Control
    [19] WDT_RESET2 write-1-sets — Resets counter 2 back to 0000. Hardware will reset this bit after counter was reset. This will take up to one LFCLK cycle to take effect.
    [17] WDT_ENABLED2 ro — Indicates actual state of counter. May lag WDT_ENABLE2 by up to two LFCLK cycles.
    [16] WDT_ENABLE2 — Enable subcounter 2. May take up to 2 LFCLK cycles to take effect. 0: Counter is disabled (not clocked) 1: Counter is enabled (counting up)
    [11] WDT_RESET1 write-1-sets — Resets counter 1 back to 0000. Hardware will reset this bit after counter was reset. This will take up to one LFCLK cycle to take effect.
    [9] WDT_ENABLED1 ro — Indicates actual state of counter. May lag WDT_ENABLE1 by up to two LFCLK cycles.
    [8] WDT_ENABLE1 — Enable subcounter 1. May take up to 2 LFCLK cycles to take effect. 0: Counter is disabled (not clocked) 1: Counter is enabled (counting up)
    [3] WDT_RESET0 write-1-sets — Resets counter 0 back to 0000. Hardware will reset this bit after counter was reset. This will take up to one LFCLK cycle to take effect.
    [1] WDT_ENABLED0 ro — Indicates actual state of counter. May lag WDT_ENABLE0 by up to two LFCLK cycles.
    [0] WDT_ENABLE0 — Enable subcounter 0. May take up to 2 LFCLK cycles to take effect. 0: Counter is disabled (not clocked) 1: Counter is enabled (counting up)
  0x18 MCWDT_INTR — Multi-Counter Watchdog Counter Interrupt Register
    [2] MCWDT_INT2 write-1-clears — MCWDT Interrupt Request for sub-counter 2. This bit is set by hardware as configured by this registers. This bit must be cleared by firmware. Clearing this bit also prevents Reset from happening when WDT_MODE2=3.
    [1] MCWDT_INT1 write-1-clears — MCWDT Interrupt Request for sub-counter 1. This bit is set by hardware as configured by this registers. This bit must be cleared by firmware. Clearing this bit also prevents Reset from happening when WDT_MODE1=3.
    [0] MCWDT_INT0 write-1-clears — MCWDT Interrupt Request for sub-counter 0. This bit is set by hardware as configured by this registers. This bit must be cleared by firmware. Clearing this bit also prevents Reset from happening when WDT_MODE0=3.
  0x1C MCWDT_INTR_SET — Multi-Counter Watchdog Counter Interrupt Set Register
    [2] MCWDT_INT2 write-1-sets — Set interrupt for MCWDT_INT2
    [1] MCWDT_INT1 write-1-sets — Set interrupt for MCWDT_INT1
    [0] MCWDT_INT0 write-1-sets — Set interrupt for MCWDT_INT0
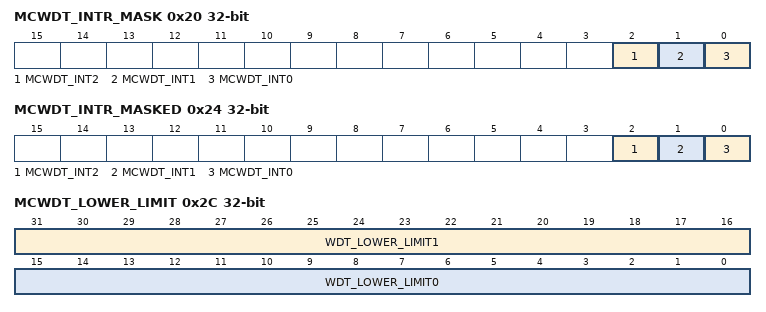
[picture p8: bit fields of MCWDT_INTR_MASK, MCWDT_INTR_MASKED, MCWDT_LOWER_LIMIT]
  0x20 MCWDT_INTR_MASK — Multi-Counter Watchdog Counter Interrupt Mask Register
    [2] MCWDT_INT2 — Mask for sub-counter 2. This controls if the interrupt is forwarded to the CPU. 0: Interrupt is masked (not forwarded). 1: Interrupt is forwarded.
    [1] MCWDT_INT1 — Mask for sub-counter 1. This controls if the interrupt is forwarded to the CPU. 0: Interrupt is masked (not forwarded). 1: Interrupt is forwarded.
    [0] MCWDT_INT0 — Mask for sub-counter 0. This controls if the interrupt is forwarded to the CPU. 0: Interrupt is masked (not forwarded). 1: Interrupt is forwarded.
  0x24 MCWDT_INTR_MASKED ro — Multi-Counter Watchdog Counter Interrupt Masked Register
    [2] MCWDT_INT2 — Logical and of corresponding request and mask bits.
    [1] MCWDT_INT1 — Logical and of corresponding request and mask bits.
    [0] MCWDT_INT0 — Logical and of corresponding request and mask bits.
  0x28 MCWDT_LOCK — Multi-Counter Watchdog Counter Lock Register
    [31:30] MCWDT_LOCK — Prohibits writing control and configuration registers related to this MCWDT when not equal 0 (as specified in the other register descriptions). Requires at least two different writes to unlock. Note that this field is 2 bits to force multiple writes only. Each MCWDT has a separate local lock. LFCLK settings are locked by the global WDT_LOCK register, and this register has no effect on that.
      values as WDT_CTL.WDT_LOCK
  0x2C MCWDT_LOWER_LIMIT — Multi-Counter Watchdog Counter Lower Limit Register
    [31:16] WDT_LOWER_LIMIT1 — Lower limit for sub-counter 1 of this MCWDT
    [15:0] WDT_LOWER_LIMIT0 — Lower limit for sub-counter 0 of this MCWDT
